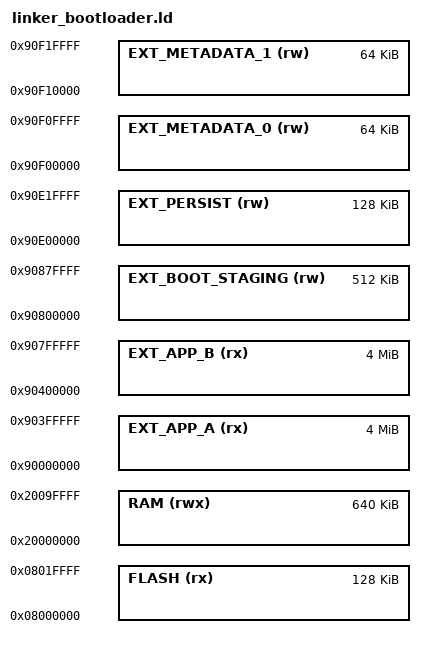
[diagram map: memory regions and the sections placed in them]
/* STM32H5 external-flash template. Configure XSPI and TrustZone policy during porting. */
MEMORY
{
  FLASH (rx) : ORIGIN = 0x08000000, LENGTH = 128K
  EXT_APP_A (rx) : ORIGIN = 0x90000000, LENGTH = 4096K
  EXT_APP_B (rx) : ORIGIN = 0x90400000, LENGTH = 4096K
  EXT_BOOT_STAGING (rw) : ORIGIN = 0x90800000, LENGTH = 512K
  EXT_PERSIST (rw) : ORIGIN = 0x90E00000, LENGTH = 128K
  EXT_METADATA_0 (rw) : ORIGIN = 0x90F00000, LENGTH = 64K
  EXT_METADATA_1 (rw) : ORIGIN = 0x90F10000, LENGTH = 64K
  RAM (rwx)  : ORIGIN = 0x20000000, LENGTH = 640K
}
